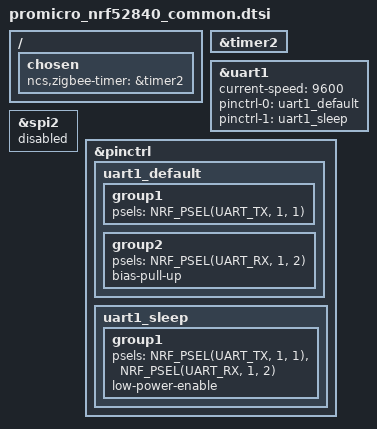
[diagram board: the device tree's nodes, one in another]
/*
 * Copyright (c) 2026 Nordic Semiconductor ASA
 *
 * SPDX-License-Identifier: LicenseRef-Nordic-5-Clause
 */

/*
 * Board setup that is the same for every promicro_nrf52840 board variant:
 * the Zigbee timer and the ISCP link to the receiver. Included from the
 * per-variant overlays, which add the flash layout they need.
 */

/ {
	chosen {
		ncs,zigbee-timer = &timer2;
	};
};

&timer2 {
	status = "okay";
};

/* ISCP link to the receiver: 9600 baud, 8N1, '!' <unit> <command> <parameter>
 * '\r' frames. The Pro Micro nRF52840 breaks out no dedicated serial port, so
 * the link uses the SPI2 pins, which this application does not need.
 */
&uart1 {
	status = "okay";
	current-speed = <9600>;
	pinctrl-0 = <&uart1_default>;
	pinctrl-1 = <&uart1_sleep>;
	pinctrl-names = "default", "sleep";
};

&spi2 {
	/* Owned by the ISCP UART. */
	status = "disabled";
};

&pinctrl {
	uart1_default: uart1_default {
		group1 {
			psels = <NRF_PSEL(UART_TX, 1, 1)>;
		};

		group2 {
			psels = <NRF_PSEL(UART_RX, 1, 2)>;
			bias-pull-up;
		};
	};

	uart1_sleep: uart1_sleep {
		group1 {
			psels = <NRF_PSEL(UART_TX, 1, 1)>,
				<NRF_PSEL(UART_RX, 1, 2)>;
			low-power-enable;
		};
	};
};
